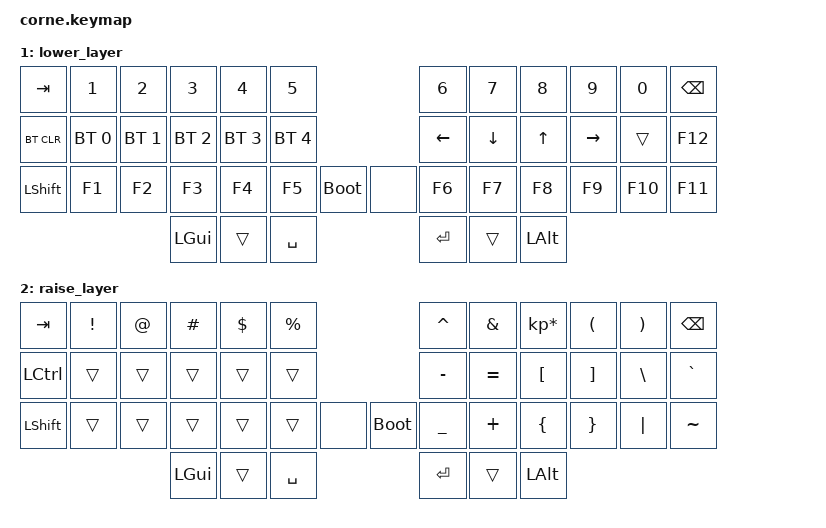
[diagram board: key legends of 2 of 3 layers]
#include <behaviors.dtsi>
#include <dt-bindings/zmk/keys.h>
#include <dt-bindings/zmk/bt.h>

// Home row mod macros
#define HRML(k1,k2,k3,k4) &ht LGUI k1 &ht LALT k2 &ht LCTRL k3 &ht LSHFT k4
#define HRMR(k1,k2,k3,k4) &ht RSHFT k1 &ht RCTRL k2 &ht LRALT k3 &ht RGUI k4

/ {
        behaviors {
            ht: hold_tap {
                label = "hold_tap";
                compatible = "zmk,behavior-hold-tap";
                #binding-cells = <2>;
                flavor = "tap-preferred";
                tapping-term-ms = <220>;
                quick-tap-ms = <150>;
                qlobal-quick-tap;
                bindings = <&kp>, <&kp>;
            }
        }

        keymap {
        	compatible = "zmk,keymap";
			default_layer {
				bindings = <
			//	------------------------------------------------------------------------------------------------
			//	|	TAB		|	Q		|	W		|  	E		|	R		|	T		|           	|			|	Y		|	U		|	I		|	O		|	P		|	BKSP	|
				&kp TAB		&kp Q 		&kp W 		&kp E 		&kp R 		&kp T                   				&kp Y		&kp U		&kp I		&kp O		&kp P		&kp BSPC
			// 	|	CTRL	| 	A 		|	S		|	D		|	F		|	G		|               |			| 	H		|  	J		|  	K  		|  	L  		|  	;  		|  	'   	|
				&kp LCTRL	HRML(A,			S,			D,			F)		&kp G                   				&kp H 		HRMR(J,  		K,     		L,   			SEMI) 	&kp SQT
			//	|	SHFT	|	Z		|	X		|	C		|	V		|	B		|	MUTE	|	|        	|  	N  		|  	M   	|  	,  		|  	.  		|  	/  		| 	ESC  	|
				&kp	LSHFT	&kp Z		&kp X		&kp C		&kp V		&kp B		&kp C_MUTE  	&none 		&kp N 		&kp M  		&kp COMMA 	&kp DOT 	&kp FSLH 	&kp ESC
			//                  								|	GUI		|	LWR		|	SPC		|	|	ENT 	| 	RSE  	| 	ALT 	|
																&kp LGUI	&mo 1		&kp SPACE       &kp RET 	&mo 2 		&kp LALT
   				>;
				sensor-bindings = <&inc_dec_kp C_VOL_UP C_VOL_DN &inc_dec_kp PG_UP PG_DN>;
                };
			lower_layer {
// ------------------------------------------------------------------------------------------------
// |  TAB |  1  |  2  |  3  |  4  |  5  |                    |  6  |  7  |  8  |  9  |  0  | BKSP |
// | BTCLR| BT1 | BT2 | BT3 | BT4 | BT5 |                    | LFT | DWN |  UP | RGT |     |  F12 |
// | SHFT | F1  | F2  | F3  | F4  | F5  |  boot  |  |        |  F6 | F7  | F8  | F9  | F10 |  F11 |
//                    | GUI |     | SPC |                    | ENT |     | ALT |
                        bindings = <
   &kp TAB    &kp N1       &kp N2       &kp N3       &kp N4       &kp N5                           &kp N6   &kp N7   &kp N8 &kp N9    &kp N0  &kp BSPC
   &bt BT_CLR &bt BT_SEL 0 &bt BT_SEL 1 &bt BT_SEL 2 &bt BT_SEL 3 &bt BT_SEL 4                     &kp LEFT &kp DOWN &kp UP &kp RIGHT &trans  &kp F12
   &kp LSHFT  &kp F1       &kp F2       &kp F3       &kp F4       &kp F5       &bootloader  &none  &kp F6   &kp F7   &kp F8 &kp F9    &kp F10 &kp F11
                                    &kp LGUI     &trans       &kp SPACE                            &kp RET  &trans   &kp LALT
                        >;

                        sensor-bindings = <&inc_dec_kp C_VOL_UP C_VOL_DN &inc_dec_kp PG_UP PG_DN>;
                };

                raise_layer {
// ------------------------------------------------------------------------------------------------
// |  TAB |  !  |  @  |  #  |  $  |  %  |                    |  ^  |  &  |  *  |  (  |  )  | BKSP |
// | CTRL |     |     |     |     |     |                    |  -  |  =  |  [  |  ]  |  \  |  `   |
// | SHFT |     |     |     |     |     |        |  |  boot  |  _  |  +  |  {  |  }  | "|" |  ~   |
//                    | GUI |     | SPC |                    | ENT |     | ALT |
                        bindings = <
   &kp  TAB  &kp EXCL &kp AT &kp HASH &kp DLLR &kp PRCNT                    &kp CARET &kp AMPS  &kp KP_MULTIPLY &kp LPAR &kp RPAR &kp BSPC
   &kp LCTRL &trans   &trans &trans   &trans   &trans                       &kp MINUS &kp EQUAL &kp LBKT        &kp RBKT &kp BSLH &kp GRAVE
   &kp LSHFT &trans   &trans &trans   &trans   &trans    &none  &bootloader &kp UNDER &kp PLUS  &kp LBRC        &kp RBRC &kp PIPE &kp TILDE
                             &kp LGUI &trans   &kp SPACE                    &kp RET   &trans    &kp LALT
                        >;

                        sensor-bindings = <&inc_dec_kp C_VOL_UP C_VOL_DN &inc_dec_kp PG_UP PG_DN>;
                };
        };
};
